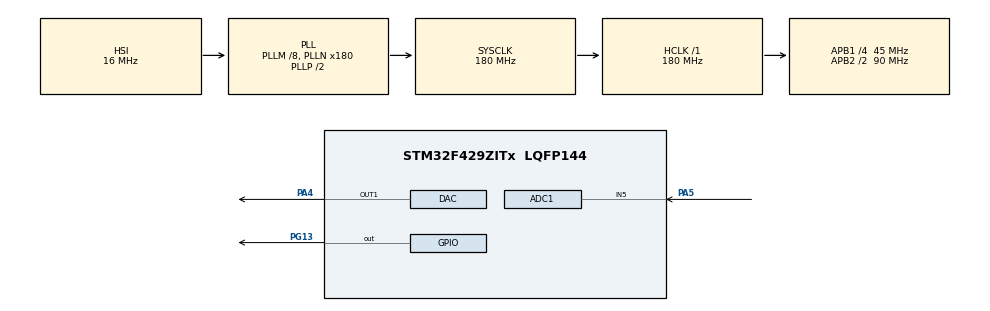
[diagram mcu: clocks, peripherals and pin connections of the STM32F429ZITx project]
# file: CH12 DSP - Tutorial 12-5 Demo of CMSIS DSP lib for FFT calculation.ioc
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ADC1.Channel-0\#ChannelRegularConversion=ADC_CHANNEL_5
ADC1.DMAContinuousRequests=ENABLE
ADC1.ExternalTrigConv=ADC_EXTERNALTRIGCONV_T8_TRGO
ADC1.NbrOfConversionFlag=1
ADC1.Rank-0\#ChannelRegularConversion=1
ADC1.SamplingTime-0\#ChannelRegularConversion=ADC_SAMPLETIME_3CYCLES
ADC1.master=1
DAC.DAC_Trigger=DAC_TRIGGER_T8_TRGO
Dma.ADC1.0.Direction=DMA_PERIPH_TO_MEMORY
Dma.ADC1.0.FIFOMode=DMA_FIFOMODE_DISABLE
Dma.ADC1.0.Instance=DMA2_Stream0
Dma.ADC1.0.MemDataAlignment=DMA_MDATAALIGN_HALFWORD
Dma.ADC1.0.MemInc=DMA_MINC_ENABLE
Dma.ADC1.0.Mode=DMA_CIRCULAR
Dma.ADC1.0.PeriphDataAlignment=DMA_PDATAALIGN_HALFWORD
Dma.ADC1.0.PeriphInc=DMA_PINC_DISABLE
Dma.ADC1.0.Priority=DMA_PRIORITY_LOW
Dma.DAC1.1.Direction=DMA_MEMORY_TO_PERIPH
Dma.DAC1.1.FIFOMode=DMA_FIFOMODE_DISABLE
Dma.DAC1.1.Instance=DMA1_Stream5
Dma.DAC1.1.MemDataAlignment=DMA_MDATAALIGN_WORD
Dma.DAC1.1.MemInc=DMA_MINC_ENABLE
Dma.DAC1.1.Mode=DMA_CIRCULAR
Dma.DAC1.1.PeriphDataAlignment=DMA_PDATAALIGN_WORD
Dma.DAC1.1.PeriphInc=DMA_PINC_DISABLE
Dma.DAC1.1.Priority=DMA_PRIORITY_LOW
Dma.Request0=ADC1
Dma.Request1=DAC1
Mcu.Family=STM32F4
Mcu.Name=STM32F429ZITx
Mcu.Package=LQFP144
NVIC.ADC_IRQn=true\:1\:0\:true\:false\:true\:true\:true\:true
NVIC.DMA1_Stream5_IRQn=true\:1\:0\:true\:false\:true\:false\:true\:true
NVIC.DMA2_Stream0_IRQn=true\:1\:0\:true\:false\:true\:false\:true\:true
NVIC.PriorityGroup=NVIC_PRIORITYGROUP_1
PA4.Signal=COMP_DAC1_group
PA5.Signal=ADCx_IN5
PG13.Signal=GPIO_Output
ProjectManager.HeapSize=0x200
ProjectManager.StackSize=0x400
ProjectManager.TargetToolchain=STM32CubeIDE
RCC.48MHZClocksFreq_Value=51428571.428571425
RCC.AHBFreq_Value=180000000
RCC.APB1CLKDivider=RCC_HCLK_DIV4
RCC.APB1Freq_Value=45000000
RCC.APB1TimFreq_Value=90000000
RCC.APB2CLKDivider=RCC_HCLK_DIV2
RCC.APB2Freq_Value=90000000
RCC.APB2TimFreq_Value=180000000
RCC.CortexFreq_Value=180000000
RCC.HCLKFreq_Value=180000000
RCC.HSE_VALUE=8000000
RCC.HSI_VALUE=16000000
RCC.LSE_VALUE=32768
RCC.PLLM=8
RCC.PLLN=180
RCC.PLLQ=7
RCC.SYSCLKFreq_VALUE=180000000
RCC.SYSCLKSource=RCC_SYSCLKSOURCE_PLLCLK
RCC.VCOOutputFreq_Value=360000000
SH.ADCx_IN5.0=ADC1_IN5,IN5
SH.COMP_DAC1_group.0=DAC_OUT1,DAC_OUT1
TIM8.Period=100-1
TIM8.Prescaler=180-1
TIM8.TIM_MasterOutputTrigger=TIM_TRGO_UPDATE
VP_TIM8_VS_ClockSourceINT.Mode=Internal
board=STM32F429I-DISC1

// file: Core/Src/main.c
/* USER CODE BEGIN Header */
/**
  ******************************************************************************
  * @file           : main.c
  * @brief          : Main program body
  ******************************************************************************
  * @attention
  *
  * Copyright (c) 2024 STMicroelectronics.
  * All rights reserved.
  *
  * This software is licensed under terms that can be found in the LICENSE file
  * in the root directory of this software component.
  * If no LICENSE file comes with this software, it is provided AS-IS.
  *
  ******************************************************************************
  */

	/***************************** Tutorial Tags ******************************
	 Data communication ADC with DMA
	 Timer trigger out event (trigger ADC sampling)
	 GPIO digital output
	 **************************************************************************/

	/* 9.4.5 DMA Usage in C Language: ******************************************
	* Tutorial 9-15: Obtaining ADC data using the DMA module
	*

    In this tutorial on peripheral unit to memory transfer using the ADC module module
    form a project with the following specificvation:

    Here, consecutive 16 ADC conversion operations are done by the help of
	DMA. Then, average of the obtained samples is calculated as voltage. If the average
	voltage level is higher than 2 V, the green LED connected to pin PG13 of the
	STM32F4 board is turned on. It will be turned off otherwise. We will trigger the
	ADC module with the Timer 2 module. Here, the sampling frequency will be set
	as 1 kHz.

	***************************************************************************/
/* USER CODE END Header */
#include "main.h"

/* USER CODE BEGIN Includes */
#define ARM_MATH_CM4

#include "arm_math.h"
/* USER CODE END Includes */

/* USER CODE BEGIN PD */
#define length 16
/* USER CODE END PD */

ADC_HandleTypeDef hadc1;
DMA_HandleTypeDef hdma_adc1;

DAC_HandleTypeDef hdac;
DMA_HandleTypeDef hdma_dac1;

TIM_HandleTypeDef htim8;

/* USER CODE BEGIN PV */
uint16_t  pData[length];
float Ave;

int i;
float arr[1024];
float arr2[1024];
float arr3[512];

/* USER CODE END PV */

void SystemClock_Config(void);
static void MX_GPIO_Init(void);
static void MX_DMA_Init(void);
static void MX_ADC1_Init(void);
static void MX_TIM8_Init(void);
static void MX_DAC_Init(void);

int main(void)
{

  /* MCU Configuration--------------------------------------------------------*/

  /* Reset of all peripherals, Initializes the Flash interface and the Systick. */
  HAL_Init();

  /* Configure the system clock */
  SystemClock_Config();

  /* Initialize all configured peripherals */
  MX_GPIO_Init();
  MX_DMA_Init();
  MX_ADC1_Init();
  MX_TIM8_Init();
  MX_DAC_Init();
  /* USER CODE BEGIN 2 */
  /* Start ADC sampling using DMA */
  HAL_ADC_Start_DMA(&hadc1, (uint32_t *) pData, length);

  /* Start timer for sampling frequency of 1 kHz */
  //HAL_TIM_Base_Start(&htim8);

  for (i = 0; i < 1024; i++)
  {
  arr[i] = arm_sin_f32(2 * PI * i * 50 / 1024) + 5;
  }
  arm_rfft_fast_instance_f32 S;
  arm_rfft_fast_init_f32(&S, 1024);
  arm_rfft_fast_f32(&S, arr, arr2, 0);
  arm_cmplx_mag_f32(arr2, arr3, 512);
  /* USER CODE END 2 */

  /* USER CODE END 2 */

  /* Infinite loop */
  while (1)
  {

  }
}

void SystemClock_Config(void)
{
  RCC_OscInitTypeDef RCC_OscInitStruct = {0};
  RCC_ClkInitTypeDef RCC_ClkInitStruct = {0};

  /** Configure the main internal regulator output voltage
  */
  __HAL_RCC_PWR_CLK_ENABLE();
  __HAL_PWR_VOLTAGESCALING_CONFIG(PWR_REGULATOR_VOLTAGE_SCALE1);

  /** Initializes the RCC Oscillators according to the specified parameters
  * in the RCC_OscInitTypeDef structure.
  */
  RCC_OscInitStruct.OscillatorType = RCC_OSCILLATORTYPE_HSI;
  RCC_OscInitStruct.HSIState = RCC_HSI_ON;
  RCC_OscInitStruct.HSICalibrationValue = RCC_HSICALIBRATION_DEFAULT;
  RCC_OscInitStruct.PLL.PLLState = RCC_PLL_ON;
  RCC_OscInitStruct.PLL.PLLSource = RCC_PLLSOURCE_HSI;
  RCC_OscInitStruct.PLL.PLLM = 8;
  RCC_OscInitStruct.PLL.PLLN = 180;
  RCC_OscInitStruct.PLL.PLLP = RCC_PLLP_DIV2;
  RCC_OscInitStruct.PLL.PLLQ = 7;
  if (HAL_RCC_OscConfig(&RCC_OscInitStruct) != HAL_OK)
  {
    Error_Handler();
  }

  /** Activate the Over-Drive mode
  */
  if (HAL_PWREx_EnableOverDrive() != HAL_OK)
  {
    Error_Handler();
  }

  /** Initializes the CPU, AHB and APB buses clocks
  */
  RCC_ClkInitStruct.ClockType = RCC_CLOCKTYPE_HCLK|RCC_CLOCKTYPE_SYSCLK
                              |RCC_CLOCKTYPE_PCLK1|RCC_CLOCKTYPE_PCLK2;
  RCC_ClkInitStruct.SYSCLKSource = RCC_SYSCLKSOURCE_PLLCLK;
  RCC_ClkInitStruct.AHBCLKDivider = RCC_SYSCLK_DIV1;
  RCC_ClkInitStruct.APB1CLKDivider = RCC_HCLK_DIV4;
  RCC_ClkInitStruct.APB2CLKDivider = RCC_HCLK_DIV2;

  if (HAL_RCC_ClockConfig(&RCC_ClkInitStruct, FLASH_LATENCY_5) != HAL_OK)
  {
    Error_Handler();
  }
}

static void MX_ADC1_Init(void)
{

  ADC_ChannelConfTypeDef sConfig = {0};

  /** Configure the global features of the ADC (Clock, Resolution, Data Alignment and number of conversion)
  */
  hadc1.Instance = ADC1;
  hadc1.Init.ClockPrescaler = ADC_CLOCK_SYNC_PCLK_DIV4;
  hadc1.Init.Resolution = ADC_RESOLUTION_12B;
  hadc1.Init.ScanConvMode = DISABLE;
  hadc1.Init.ContinuousConvMode = DISABLE;
  hadc1.Init.DiscontinuousConvMode = DISABLE;
  hadc1.Init.ExternalTrigConvEdge = ADC_EXTERNALTRIGCONVEDGE_RISING;
  hadc1.Init.ExternalTrigConv = ADC_EXTERNALTRIGCONV_T8_TRGO;
  hadc1.Init.DataAlign = ADC_DATAALIGN_RIGHT;
  hadc1.Init.NbrOfConversion = 1;
  hadc1.Init.DMAContinuousRequests = ENABLE;
  hadc1.Init.EOCSelection = ADC_EOC_SINGLE_CONV;
  if (HAL_ADC_Init(&hadc1) != HAL_OK)
  {
    Error_Handler();
  }

  /** Configure for the selected ADC regular channel its corresponding rank in the sequencer and its sample time.
  */
  sConfig.Channel = ADC_CHANNEL_5;
  sConfig.Rank = 1;
  sConfig.SamplingTime = ADC_SAMPLETIME_3CYCLES;
  if (HAL_ADC_ConfigChannel(&hadc1, &sConfig) != HAL_OK)
  {
    Error_Handler();
  }

}

static void MX_DAC_Init(void)
{

  DAC_ChannelConfTypeDef sConfig = {0};

  /** DAC Initialization
  */
  hdac.Instance = DAC;
  if (HAL_DAC_Init(&hdac) != HAL_OK)
  {
    Error_Handler();
  }

  /** DAC channel OUT1 config
  */
  sConfig.DAC_Trigger = DAC_TRIGGER_T8_TRGO;
  sConfig.DAC_OutputBuffer = DAC_OUTPUTBUFFER_ENABLE;
  if (HAL_DAC_ConfigChannel(&hdac, &sConfig, DAC_CHANNEL_1) != HAL_OK)
  {
    Error_Handler();
  }

}

static void MX_TIM8_Init(void)
{

  TIM_ClockConfigTypeDef sClockSourceConfig = {0};
  TIM_MasterConfigTypeDef sMasterConfig = {0};

  htim8.Instance = TIM8;
  htim8.Init.Prescaler = 180-1;
  htim8.Init.CounterMode = TIM_COUNTERMODE_UP;
  htim8.Init.Period = 100-1;
  htim8.Init.ClockDivision = TIM_CLOCKDIVISION_DIV1;
  htim8.Init.RepetitionCounter = 0;
  htim8.Init.AutoReloadPreload = TIM_AUTORELOAD_PRELOAD_DISABLE;
  if (HAL_TIM_Base_Init(&htim8) != HAL_OK)
  {
    Error_Handler();
  }
  sClockSourceConfig.ClockSource = TIM_CLOCKSOURCE_INTERNAL;
  if (HAL_TIM_ConfigClockSource(&htim8, &sClockSourceConfig) != HAL_OK)
  {
    Error_Handler();
  }
  sMasterConfig.MasterOutputTrigger = TIM_TRGO_UPDATE;
  sMasterConfig.MasterSlaveMode = TIM_MASTERSLAVEMODE_DISABLE;
  if (HAL_TIMEx_MasterConfigSynchronization(&htim8, &sMasterConfig) != HAL_OK)
  {
    Error_Handler();
  }

}

static void MX_DMA_Init(void)
{

  /* DMA controller clock enable */
  __HAL_RCC_DMA2_CLK_ENABLE();
  __HAL_RCC_DMA1_CLK_ENABLE();

  /* DMA interrupt init */
  /* DMA1_Stream5_IRQn interrupt configuration */
  HAL_NVIC_SetPriority(DMA1_Stream5_IRQn, 1, 0);
  HAL_NVIC_EnableIRQ(DMA1_Stream5_IRQn);
  /* DMA2_Stream0_IRQn interrupt configuration */
  HAL_NVIC_SetPriority(DMA2_Stream0_IRQn, 1, 0);
  HAL_NVIC_EnableIRQ(DMA2_Stream0_IRQn);

}

static void MX_GPIO_Init(void)
{
  GPIO_InitTypeDef GPIO_InitStruct = {0};

  /* GPIO Ports Clock Enable */
  __HAL_RCC_GPIOA_CLK_ENABLE();
  __HAL_RCC_GPIOG_CLK_ENABLE();

  /*Configure GPIO pin Output Level */
  HAL_GPIO_WritePin(GPIOG, GPIO_PIN_13, GPIO_PIN_RESET);

  /*Configure GPIO pin : PG13 */
  GPIO_InitStruct.Pin = GPIO_PIN_13;
  GPIO_InitStruct.Mode = GPIO_MODE_OUTPUT_PP;
  GPIO_InitStruct.Pull = GPIO_NOPULL;
  GPIO_InitStruct.Speed = GPIO_SPEED_FREQ_LOW;
  HAL_GPIO_Init(GPIOG, &GPIO_InitStruct);

}

/* USER CODE BEGIN 4 */
void HAL_ADC_ConvCpltCallback(ADC_HandleTypeDef *hadc)
{

}
/* USER CODE END 4 */

void Error_Handler(void)
{
  __disable_irq();
  while (1)
  {
  }
}
